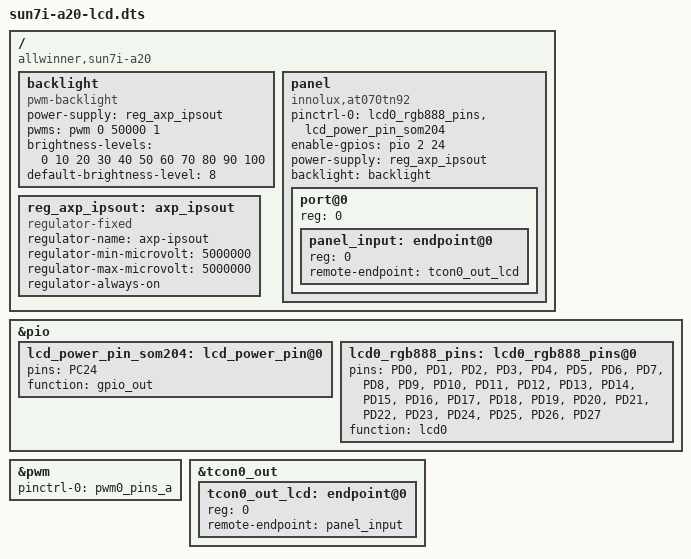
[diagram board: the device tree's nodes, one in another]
/dts-v1/;
/plugin/;

/ {
	compatible = "allwinner,sun7i-a20";

	fragment@0 {
		target-path = "/";
		__overlay__ {
			backlight: backlight {
				compatible = "pwm-backlight";
				power-supply = <&reg_axp_ipsout>;
				pwms = <&pwm 0 50000 1>;
				brightness-levels = <0 10 20 30 40 50 60 70 80 90 100>;
				default-brightness-level = <8>;
			};
		};
	};

	fragment@1 {
		target-path = "/";
		__overlay__ {
			panel {
				compatible = "innolux,at070tn92";
				#address-cells = <1>;
				#size-cells = <0>;
				pinctrl-names = "default";
				pinctrl-0 = <&lcd0_rgb888_pins>, <&lcd_power_pin_som204>;
				status = "okay";

				enable-gpios = <&pio 2 24 0>;
				power-supply = <&reg_axp_ipsout>;

				backlight = <&backlight>;

				port@0 {
					#address-cells = <1>;
					#size-cells = <0>;
					reg = <0>;

					panel_input: endpoint@0 {
						reg = <0>;
						remote-endpoint = <&tcon0_out_lcd>;
					};
				};
			};
		};
	};

	fragment@2 {
		target-path = "/";
		__overlay__ {
			reg_axp_ipsout: axp_ipsout {
				compatible = "regulator-fixed";
				regulator-name = "axp-ipsout";
				regulator-min-microvolt = <5000000>;
				regulator-max-microvolt = <5000000>;
				regulator-always-on;
			};
		};
	};

	fragment@3 {
		target = <&pio>;
		__overlay__ {
			lcd_power_pin_som204: lcd_power_pin@0 {
				pins = "PC24";
				function = "gpio_out";
			};

			lcd0_rgb888_pins: lcd0_rgb888_pins@0 {
				pins = "PD0", "PD1", "PD2", "PD3", "PD4", "PD5", "PD6", "PD7",
					"PD8", "PD9", "PD10", "PD11", "PD12", "PD13", "PD14", "PD15",
					"PD16", "PD17", "PD18", "PD19", "PD20", "PD21", "PD22", "PD23",
					"PD24", "PD25", "PD26", "PD27";
				function = "lcd0";
			};
		};
	};

	fragment@4 {
		target = <&pwm>;
		__overlay__ {
			pinctrl-names = "default";
			pinctrl-0 = <&pwm0_pins_a>;
			status = "okay";
		};
	};

	fragment@5 {
		target = <&tcon0_out>;
		__overlay__ {
			tcon0_out_lcd: endpoint@0 {
				reg = <0>;
				remote-endpoint = <&panel_input>;
			};
		};
	};
};
